AUTOSAR XML (schema 00048)
package /ComponentTypes
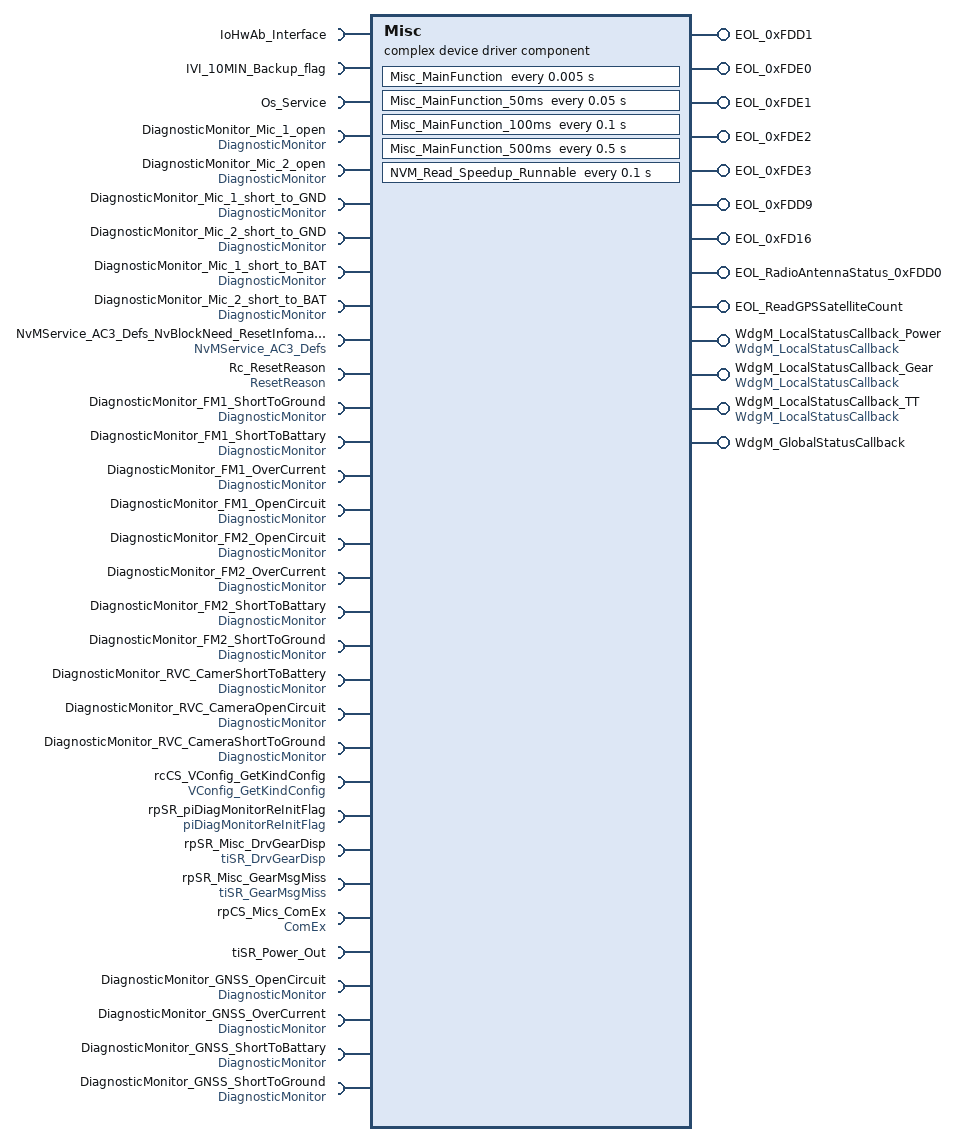
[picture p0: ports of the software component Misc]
  complex device driver sw component type Misc
    require port IoHwAb_Interface: required-com-specs=[SetHsLsOutput, SetPeriodAndDuty, SetDuty, SetPin, GetPin, GetVoltage], required-interface=IoHwAb_Interface
    require port IVI_10MIN_Backup_flag: nonqueued-receiver-com-spec{data-element=Element, filter=data-filter-type=ALWAYS, init-value=0}, required-interface=IVI_10MIN_Backup_flag
    require port Os_Service: required-com-specs=[GetElapsedValue, GetCounterValue], required-interface=Os_Service
    8 x provide port:
      EOL_0xFDD1: server-com-spec{operation=EOL_ReadMICStatus, queue-length=1}, provided-interface=EOL_0xFDD1
      EOL_0xFDE0: provided-interface=EOL_0xFDE0
      EOL_0xFDE1: server-com-spec{operation=EOL_ReadWatchDogCnt, queue-length=1}, provided-interface=EOL_0xFDE1
      EOL_0xFDE2: server-com-spec{operation=EOL_ReadResetInformation, queue-length=1}, provided-interface=EOL_0xFDE2
      EOL_0xFDE3: provided-interface=EOL_0xFDE3
      EOL_0xFDD9: server-com-spec{operation=EOL_WriteValueForDispalyEnable, queue-length=1}, provided-interface=EOL_0xFDD9
      EOL_0xFD16: server-com-spec{operation=EOL_FactoryReset, queue-length=1}, provided-interface=EOL_0xFD16
      EOL_RadioAntennaStatus_0xFDD0: nonqueued-sender-com-spec{data-element=RadioAntennaStatus_0xFDD0, init-value=[0, 0, 0]}, provided-interface=EOL_RadioAntennaStatus_0xFDD0
    8 x require port:
      DiagnosticMonitor_Mic_1_open: required-interface=DiagnosticMonitor
        required-com-specs:
          GetEventExtendedDataRecordEx
          GetEventFreezeFrameDataEx
          GetFaultDetectionCounter
          GetDTCOfEvent
          GetEventTested
          GetEventFailed
          GetEventStatus
          GetEventUdsStatus
          ResetEventDebounceStatus
          ResetEventStatus
          SetEventStatus
      DiagnosticMonitor_Mic_2_open: required-interface=DiagnosticMonitor
        required-com-specs:
          GetEventExtendedDataRecordEx
          GetEventFreezeFrameDataEx
          GetFaultDetectionCounter
          GetDTCOfEvent
          GetEventTested
          GetEventFailed
          GetEventStatus
          GetEventUdsStatus
          ResetEventDebounceStatus
          ResetEventStatus
          SetEventStatus
      DiagnosticMonitor_Mic_1_short_to_GND: required-interface=DiagnosticMonitor
        required-com-specs:
          GetEventExtendedDataRecordEx
          GetEventFreezeFrameDataEx
          GetFaultDetectionCounter
          GetDTCOfEvent
          GetEventTested
          GetEventFailed
          GetEventStatus
          GetEventUdsStatus
          ResetEventDebounceStatus
          ResetEventStatus
          SetEventStatus
      DiagnosticMonitor_Mic_2_short_to_GND: required-interface=DiagnosticMonitor
        required-com-specs:
          GetEventExtendedDataRecordEx
          GetEventFreezeFrameDataEx
          GetFaultDetectionCounter
          GetDTCOfEvent
          GetEventTested
          GetEventFailed
          GetEventStatus
          GetEventUdsStatus
          ResetEventDebounceStatus
          ResetEventStatus
          SetEventStatus
      DiagnosticMonitor_Mic_1_short_to_BAT: required-interface=DiagnosticMonitor
        required-com-specs:
          GetEventExtendedDataRecordEx
          GetEventFreezeFrameDataEx
          GetFaultDetectionCounter
          GetDTCOfEvent
          GetEventTested
          GetEventFailed
          GetEventStatus
          GetEventUdsStatus
          ResetEventDebounceStatus
          ResetEventStatus
          SetEventStatus
      DiagnosticMonitor_Mic_2_short_to_BAT: required-interface=DiagnosticMonitor
        required-com-specs:
          GetEventExtendedDataRecordEx
          GetEventFreezeFrameDataEx
          GetFaultDetectionCounter
          GetDTCOfEvent
          GetEventTested
          GetEventFailed
          GetEventStatus
          GetEventUdsStatus
          ResetEventDebounceStatus
          ResetEventStatus
          SetEventStatus
      NvMService_AC3_Defs_NvBlockNeed_ResetInfomation: required-com-specs=[WriteBlock, RestoreBlockDefaults, ReadBlock, InvalidateNvBlock, GetErrorStatus, EraseBlock], required-interface=NvMService_AC3_Defs
      Rc_ResetReason: nonqueued-receiver-com-spec{data-element=ResetSource, filter=data-filter-type=ALWAYS, init-value=0}, required-interface=ResetReason
    provide port EOL_ReadGPSSatelliteCount: nonqueued-sender-com-spec{data-element=GPSSatelliteCount, init-value=0}, provided-interface=EOL_ReadGPSSatelliteCount
    11 x require port, all with required-interface=DiagnosticMonitor:
      DiagnosticMonitor_FM1_ShortToGround
        required-com-specs:
          GetEventExtendedDataRecordEx
          GetEventFreezeFrameDataEx
          GetFaultDetectionCounter
          GetDTCOfEvent
          GetEventTested
          GetEventFailed
          GetEventStatus
          GetEventUdsStatus
          ResetEventDebounceStatus
          ResetEventStatus
          SetEventStatus
      DiagnosticMonitor_FM1_ShortToBattary
        required-com-specs:
          GetEventExtendedDataRecordEx
          GetEventFreezeFrameDataEx
          GetFaultDetectionCounter
          GetDTCOfEvent
          GetEventTested
          GetEventFailed
          GetEventStatus
          GetEventUdsStatus
          ResetEventDebounceStatus
          ResetEventStatus
          SetEventStatus
      DiagnosticMonitor_FM1_OverCurrent
        required-com-specs:
          GetEventExtendedDataRecordEx
          GetEventFreezeFrameDataEx
          GetFaultDetectionCounter
          GetDTCOfEvent
          GetEventTested
          GetEventFailed
          GetEventStatus
          GetEventUdsStatus
          ResetEventDebounceStatus
          ResetEventStatus
          SetEventStatus
      DiagnosticMonitor_FM1_OpenCircuit
        required-com-specs:
          GetEventExtendedDataRecordEx
          GetEventFreezeFrameDataEx
          GetFaultDetectionCounter
          GetDTCOfEvent
          GetEventTested
          GetEventFailed
          GetEventStatus
          GetEventUdsStatus
          ResetEventDebounceStatus
          ResetEventStatus
          SetEventStatus
      DiagnosticMonitor_FM2_OpenCircuit
        required-com-specs:
          GetEventExtendedDataRecordEx
          GetEventFreezeFrameDataEx
          GetFaultDetectionCounter
          GetDTCOfEvent
          GetEventTested
          GetEventFailed
          GetEventStatus
          GetEventUdsStatus
          ResetEventDebounceStatus
          ResetEventStatus
          SetEventStatus
      DiagnosticMonitor_FM2_OverCurrent
        required-com-specs:
          GetEventExtendedDataRecordEx
          GetEventFreezeFrameDataEx
          GetFaultDetectionCounter
          GetDTCOfEvent
          GetEventTested
          GetEventFailed
          GetEventStatus
          GetEventUdsStatus
          ResetEventDebounceStatus
          ResetEventStatus
          SetEventStatus
      DiagnosticMonitor_FM2_ShortToBattary
        required-com-specs:
          GetEventExtendedDataRecordEx
          GetEventFreezeFrameDataEx
          GetFaultDetectionCounter
          GetDTCOfEvent
          GetEventTested
          GetEventFailed
          GetEventStatus
          GetEventUdsStatus
          ResetEventDebounceStatus
          ResetEventStatus
          SetEventStatus
      DiagnosticMonitor_FM2_ShortToGround
        required-com-specs:
          GetEventExtendedDataRecordEx
          GetEventFreezeFrameDataEx
          GetFaultDetectionCounter
          GetDTCOfEvent
          GetEventTested
          GetEventFailed
          GetEventStatus
          GetEventUdsStatus
          ResetEventDebounceStatus
          ResetEventStatus
          SetEventStatus
      DiagnosticMonitor_RVC_CamerShortToBattery
        required-com-specs:
          GetEventExtendedDataRecordEx
          GetEventFreezeFrameDataEx
          GetFaultDetectionCounter
          GetDTCOfEvent
          GetEventTested
          GetEventFailed
          GetEventStatus
          GetEventUdsStatus
          ResetEventDebounceStatus
          ResetEventStatus
          SetEventStatus
      DiagnosticMonitor_RVC_CameraOpenCircuit
        required-com-specs:
          GetEventExtendedDataRecordEx
          GetEventFreezeFrameDataEx
          GetFaultDetectionCounter
          GetDTCOfEvent
          GetEventTested
          GetEventFailed
          GetEventStatus
          GetEventUdsStatus
          ResetEventDebounceStatus
          ResetEventStatus
          SetEventStatus
      DiagnosticMonitor_RVC_CameraShortToGround
        required-com-specs:
          GetEventExtendedDataRecordEx
          GetEventFreezeFrameDataEx
          GetFaultDetectionCounter
          GetDTCOfEvent
          GetEventTested
          GetEventFailed
          GetEventStatus
          GetEventUdsStatus
          ResetEventDebounceStatus
          ResetEventStatus
          SetEventStatus
    4 x provide port:
      WdgM_LocalStatusCallback_Power: server-com-spec{operation=LocalStatusCallback, queue-length=1}, provided-interface=WdgM_LocalStatusCallback
      WdgM_LocalStatusCallback_Gear: server-com-spec{operation=LocalStatusCallback, queue-length=1}, provided-interface=WdgM_LocalStatusCallback
      WdgM_LocalStatusCallback_TT: server-com-spec{operation=LocalStatusCallback, queue-length=1}, provided-interface=WdgM_LocalStatusCallback
      WdgM_GlobalStatusCallback: server-com-spec{operation=GlobalStatusCallback, queue-length=1}, provided-interface=WdgM_GlobalStatusCallback
    10 x require port:
      rcCS_VConfig_GetKindConfig: client-com-spec=Operation_VConfig_GetKindConfig, required-interface=VConfig_GetKindConfig
      rpSR_piDiagMonitorReInitFlag: nonqueued-receiver-com-spec{data-element=ChangeCounter, filter=data-filter-type=ALWAYS, init-value=0}, required-interface=piDiagMonitorReInitFlag
      rpSR_Misc_DrvGearDisp: nonqueued-receiver-com-spec{data-element=Element, filter=data-filter-type=ALWAYS}, required-interface=tiSR_DrvGearDisp
      rpSR_Misc_GearMsgMiss: nonqueued-receiver-com-spec{data-element=Element, filter=data-filter-type=ALWAYS}, required-interface=tiSR_GearMsgMiss
      rpCS_Mics_ComEx: required-com-specs=[SendSignal, ReceiveSignal, GetRxE2EStatus], required-interface=ComEx
      tiSR_Power_Out: nonqueued-receiver-com-spec{data-element=SystemStateOut, filter=data-filter-type=ALWAYS, init-value=constant-reference=PowerOutInit}, required-interface=tiSR_Power_Out
      DiagnosticMonitor_GNSS_OpenCircuit: required-interface=DiagnosticMonitor
        required-com-specs:
          GetEventExtendedDataRecordEx
          GetEventFreezeFrameDataEx
          GetFaultDetectionCounter
          GetDTCOfEvent
          GetEventTested
          GetEventFailed
          GetEventStatus
          GetEventUdsStatus
          ResetEventDebounceStatus
          ResetEventStatus
          SetEventStatus
      DiagnosticMonitor_GNSS_OverCurrent: required-interface=DiagnosticMonitor
        required-com-specs:
          GetEventExtendedDataRecordEx
          GetEventFreezeFrameDataEx
          GetFaultDetectionCounter
          GetDTCOfEvent
          GetEventTested
          GetEventFailed
          GetEventStatus
          GetEventUdsStatus
          ResetEventDebounceStatus
          ResetEventStatus
          SetEventStatus
      DiagnosticMonitor_GNSS_ShortToBattary: required-interface=DiagnosticMonitor
        required-com-specs:
          GetEventExtendedDataRecordEx
          GetEventFreezeFrameDataEx
          GetFaultDetectionCounter
          GetDTCOfEvent
          GetEventTested
          GetEventFailed
          GetEventStatus
          GetEventUdsStatus
          ResetEventDebounceStatus
          ResetEventStatus
          SetEventStatus
      DiagnosticMonitor_GNSS_ShortToGround: required-interface=DiagnosticMonitor
        required-com-specs:
          GetEventExtendedDataRecordEx
          GetEventFreezeFrameDataEx
          GetFaultDetectionCounter
          GetDTCOfEvent
          GetEventTested
          GetEventFailed
          GetEventStatus
          GetEventUdsStatus
          ResetEventDebounceStatus
          ResetEventStatus
          SetEventStatus
    behavior Misc_InternalBehavior
      exclusive area ExclusiveArea_Misc
      ar-typed-per-instance-memorys:
        data NvBlockNeed_ResetInfomation_MirrorBlock: sw-calibration-access=READ-ONLY, type=NvmResetInformation_t
      timing event TMT_Misc_MainFunction: start-on-event=Misc_MainFunction, period=0.005
      init event Misc_InitEvent: start-on-event=Misc_Init
      timing event TMT_Misc_MainFunction_50ms: start-on-event=Misc_MainFunction_50ms, period=0.05
      5 x operation invoked event:
        OIT_EOL_0xFDE1_EOL_ReadWatchDogCnt_EOL_0xFDE1_EOL_ReadWatchDogCnt: start-on-event=EOL_0xFDE1_EOL_ReadWatchDogCnt, operation=EOL_0xFDE1.EOL_ReadWatchDogCnt
        OIT_EOL_0xFDE2_EOL_ReadResetInformation_EOL_0xFDE2_EOL_ReadResetInformation: start-on-event=EOL_0xFDE2_EOL_ReadResetInformation, operation=EOL_0xFDE2.EOL_ReadResetInformation
        OIT_EOL_0xFDD1_EOL_ReadMICStatus_EOL_0xFDD1_EOL_ReadMICStatus: start-on-event=EOL_0xFDD1_EOL_ReadMICStatus, operation=EOL_0xFDD1.EOL_ReadMICStatus
        OIT_EOL_0xFDD9_EOL_WriteValueForDispalyEnable_EOL_0xFDD9_EOL_WriteValueForDispalyEnable: start-on-event=EOL_0xFDD9_EOL_WriteValueForDispalyEnable, operation=EOL_0xFDD9.EOL_WriteValueForDispalyEnable
        OIT_EOL_0xFD16_EOL_FactoryReset_EOL_0xFD16_EOL_FactoryReset: start-on-event=EOL_0xFD16_EOL_FactoryReset, operation=EOL_0xFD16.EOL_FactoryReset
      timing event TMT_Misc_MainFunction_100ms: start-on-event=Misc_MainFunction_100ms, period=0.1
      timing event TMT_Misc_MainFunction_500ms: start-on-event=Misc_MainFunction_500ms, period=0.5
      timing event TMT_NVM_Read_Speedup_Runnable: start-on-event=NVM_Read_Speedup_Runnable, period=0.1
      4 x operation invoked event:
        OIT_WdgM_LocalStatusCallback_Power_LocalStatusCallback_WdgM_LocalStatusCallback_Power_LocalStatusCallback: start-on-event=WdgM_LocalStatusCallback_Power, operation=WdgM_LocalStatusCallback_Power.LocalStatusCallback
        OIT_WdgM_LocalStatusCallback_TT_LocalStatusCallback_WdgM_LocalStatusCallback_TT_LocalStatusCallback: start-on-event=WdgM_LocalStatusCallback_TT, operation=WdgM_LocalStatusCallback_TT.LocalStatusCallback
        OIT_WdgM_GlobalStatusCallback_GlobalStatusCallback_WdgM_GlobalStatusCallback_GlobalStatusCallback: start-on-event=WdgM_GlobalStatusCallback, operation=WdgM_GlobalStatusCallback.GlobalStatusCallback
        OIT_WdgM_LocalStatusCallback_Gear_LocalStatusCallback_WdgM_LocalStatusCallback_Gear_LocalStatusCallback: start-on-event=WdgM_LocalStatusCallback_Gear, operation=WdgM_LocalStatusCallback_Gear.LocalStatusCallback
      15 x runnable:
        Misc_MainFunction: can-enter-exclusive-area=ExclusiveArea_Misc
          data-receive-point-by-arguments:
            access REC_IVI_10MIN_Backup_flag_Element: accessed-variable=IVI_10MIN_Backup_flag.Element
          data-send-points:
            access SEND_EOL_RadioAntennaStatus_0xFDD0_RadioAntennaStatus_0xFDD0: accessed-variable=EOL_RadioAntennaStatus_0xFDD0.RadioAntennaStatus_0xFDD0
            access SEND_EOL_ReadGPSSatelliteCount_GPSSatelliteCount: accessed-variable=EOL_ReadGPSSatelliteCount.GPSSatelliteCount
          9 x sync call:
            SC_IoHwAb_Interface_GetVoltage: operation=IoHwAb_Interface.GetVoltage
            SC_Os_Service_GetCounterValue: operation=Os_Service.GetCounterValue
            SC_Os_Service_GetElapsedValue: operation=Os_Service.GetElapsedValue
            SC_NvMService_AC3_Defs_NvBlockNeed_ResetInfomation_EraseBlock: operation=NvMService_AC3_Defs_NvBlockNeed_ResetInfomation.EraseBlock
            SC_NvMService_AC3_Defs_NvBlockNeed_ResetInfomation_GetErrorStatus: operation=NvMService_AC3_Defs_NvBlockNeed_ResetInfomation.GetErrorStatus
            SC_NvMService_AC3_Defs_NvBlockNeed_ResetInfomation_InvalidateNvBlock: operation=NvMService_AC3_Defs_NvBlockNeed_ResetInfomation.InvalidateNvBlock
            SC_NvMService_AC3_Defs_NvBlockNeed_ResetInfomation_ReadBlock: operation=NvMService_AC3_Defs_NvBlockNeed_ResetInfomation.ReadBlock
            SC_NvMService_AC3_Defs_NvBlockNeed_ResetInfomation_RestoreBlockDefaults: operation=NvMService_AC3_Defs_NvBlockNeed_ResetInfomation.RestoreBlockDefaults
            SC_NvMService_AC3_Defs_NvBlockNeed_ResetInfomation_WriteBlock: operation=NvMService_AC3_Defs_NvBlockNeed_ResetInfomation.WriteBlock
        Misc_Init
        Misc_MainFunction_50ms
        EOL_0xFDE1_EOL_ReadWatchDogCnt
        EOL_0xFDE2_EOL_ReadResetInformation
        EOL_0xFDD1_EOL_ReadMICStatus
        EOL_0xFDD9_EOL_WriteValueForDispalyEnable
        EOL_0xFD16_EOL_FactoryReset
          data-receive-point-by-arguments:
            access REC_Rc_ResetReason_ResetSource: accessed-variable=Rc_ResetReason.ResetSource
        Misc_MainFunction_100ms
          data-receive-point-by-arguments:
            access REC_rpSR_piDiagMonitorReInitFlag_ChangeCounter: accessed-variable=rpSR_piDiagMonitorReInitFlag.ChangeCounter
          22 x sync call:
            SC_DiagnosticMonitor_Mic_1_open_SetEventStatus: operation=DiagnosticMonitor_Mic_1_open.SetEventStatus
            SC_DiagnosticMonitor_Mic_1_short_to_BAT_SetEventStatus: operation=DiagnosticMonitor_Mic_1_short_to_BAT.SetEventStatus
            SC_DiagnosticMonitor_Mic_1_short_to_GND_SetEventStatus: operation=DiagnosticMonitor_Mic_1_short_to_GND.SetEventStatus
            SC_DiagnosticMonitor_Mic_2_open_SetEventStatus: operation=DiagnosticMonitor_Mic_2_open.SetEventStatus
            SC_DiagnosticMonitor_Mic_2_short_to_BAT_SetEventStatus: operation=DiagnosticMonitor_Mic_2_short_to_BAT.SetEventStatus
            SC_DiagnosticMonitor_Mic_2_short_to_GND_SetEventStatus: operation=DiagnosticMonitor_Mic_2_short_to_GND.SetEventStatus
            SC_DiagnosticMonitor_FM1_OpenCircuit_SetEventStatus: operation=DiagnosticMonitor_FM1_OpenCircuit.SetEventStatus
            SC_DiagnosticMonitor_FM1_OverCurrent_SetEventStatus: operation=DiagnosticMonitor_FM1_OverCurrent.SetEventStatus
            SC_DiagnosticMonitor_FM1_ShortToBattary_SetEventStatus: operation=DiagnosticMonitor_FM1_ShortToBattary.SetEventStatus
            SC_DiagnosticMonitor_FM1_ShortToGround_SetEventStatus: operation=DiagnosticMonitor_FM1_ShortToGround.SetEventStatus
            SC_DiagnosticMonitor_FM2_OpenCircuit_SetEventStatus: operation=DiagnosticMonitor_FM2_OpenCircuit.SetEventStatus
            SC_DiagnosticMonitor_FM2_OverCurrent_SetEventStatus: operation=DiagnosticMonitor_FM2_OverCurrent.SetEventStatus
            SC_DiagnosticMonitor_FM2_ShortToBattary_SetEventStatus: operation=DiagnosticMonitor_FM2_ShortToBattary.SetEventStatus
            SC_DiagnosticMonitor_FM2_ShortToGround_SetEventStatus: operation=DiagnosticMonitor_FM2_ShortToGround.SetEventStatus
            SC_DiagnosticMonitor_RVC_CameraOpenCircuit_SetEventStatus: operation=DiagnosticMonitor_RVC_CameraOpenCircuit.SetEventStatus
            SC_DiagnosticMonitor_RVC_CameraShortToGround_SetEventStatus: operation=DiagnosticMonitor_RVC_CameraShortToGround.SetEventStatus
            SC_DiagnosticMonitor_RVC_CamerShortToBattery_SetEventStatus: operation=DiagnosticMonitor_RVC_CamerShortToBattery.SetEventStatus
            SC_rcCS_VConfig_GetKindConfig_Operation_VConfig_GetKindConfig: operation=rcCS_VConfig_GetKindConfig.Operation_VConfig_GetKindConfig
            SC_DiagnosticMonitor_GNSS_OpenCircuit_SetEventStatus: operation=DiagnosticMonitor_GNSS_OpenCircuit.SetEventStatus
            SC_DiagnosticMonitor_GNSS_OverCurrent_SetEventStatus: operation=DiagnosticMonitor_GNSS_OverCurrent.SetEventStatus
            SC_DiagnosticMonitor_GNSS_ShortToBattary_SetEventStatus: operation=DiagnosticMonitor_GNSS_ShortToBattary.SetEventStatus
            SC_DiagnosticMonitor_GNSS_ShortToGround_SetEventStatus: operation=DiagnosticMonitor_GNSS_ShortToGround.SetEventStatus
        Misc_MainFunction_500ms
          data-receive-point-by-arguments:
            access REC_rpSR_Misc_DrvGearDisp_Element: accessed-variable=rpSR_Misc_DrvGearDisp.Element
            access REC_rpSR_Misc_GearMsgMiss_Element: accessed-variable=rpSR_Misc_GearMsgMiss.Element
            access REC_tiSR_Power_Out_SystemStateOut: accessed-variable=tiSR_Power_Out.SystemStateOut
          sync call SC_IoHwAb_Interface_SetPin: operation=IoHwAb_Interface.SetPin
          sync call SC_rpCS_Mics_ComEx_ReceiveSignal: operation=rpCS_Mics_ComEx.ReceiveSignal
        NVM_Read_Speedup_Runnable
        WdgM_LocalStatusCallback_Power
        WdgM_LocalStatusCallback_TT
        WdgM_GlobalStatusCallback
        WdgM_LocalStatusCallback_Gear
      swc service dependency NvBlockNeed_ResetInfomation: assigned-ports=role-based-port-assignment={port-prototype=NvMService_AC3_Defs_NvBlockNeed_ResetInfomation, role=NvMService_AC3_Defs}
        assigned-datas:
          role=ramBlock, used-data-element=NvBlockNeed_ResetInfomation_MirrorBlock
          role=defaultValue, used-parameter-element=NvBlockNeed_ResetInfomation_DefaultValue
        service-needs:
          nv block needs NvBlockNeed_ResetInfomation: n-data-sets=0, ram-block-status-control=API, reliability=NO-PROTECTION, restore-at-start=true, store-at-shutdown=true
      shared-parameters:
        parameter data prototype NvBlockNeed_ResetInfomation_DefaultValue: sw-calibration-access=READ-WRITE, type=NvmResetInformation_t
  swc implementation Misc_Implementation: behavior=Misc_InternalBehavior
    code-descriptors:
      code Default: artifact-descriptors=autosar-engineering-object=category=SWSRC
